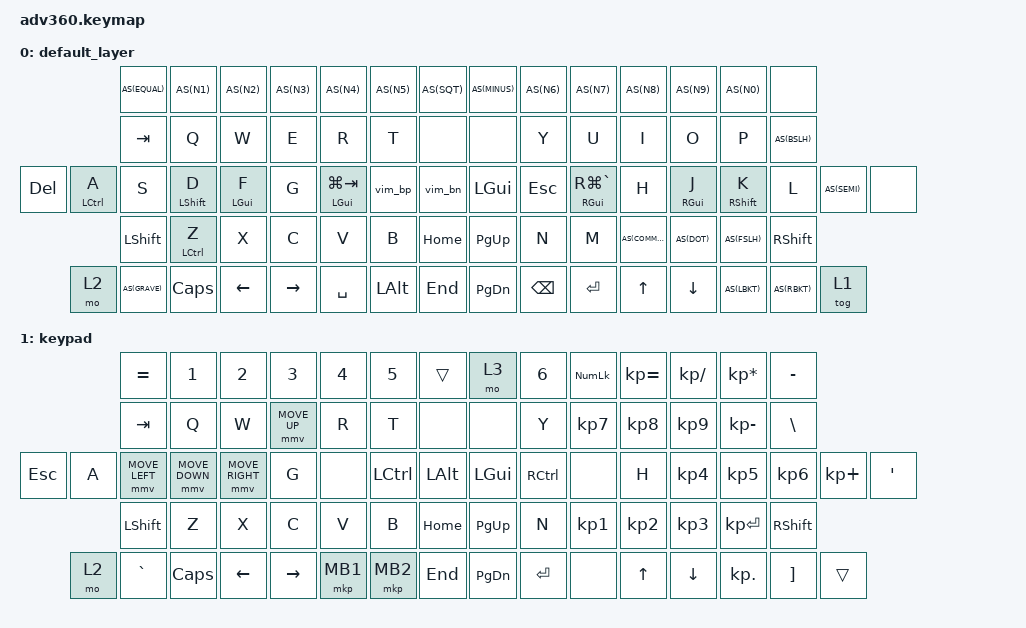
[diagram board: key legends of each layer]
#define ZMK_POINTING_DEFAULT_MOVE_VAL 2000
#include <behaviors.dtsi>
#include <dt-bindings/zmk/keys.h>
#include <dt-bindings/zmk/bt.h>
#include <dt-bindings/zmk/rgb.h>
#include <dt-bindings/zmk/stp.h>
#include <dt-bindings/zmk/backlight.h>
#include <dt-bindings/zmk/pointing.h>

#define AS(keycode) &as LS(keycode) keycode     // Autoshift Macro

#define KEYS_LEFT 0 1 2 3 4 5 6 \
                  14 15 16 17 18 19 20 \
                  28 29 30 31 32 33 34 \
                  46 47 48 49 50 51 \
                  66 67 68 69 70

#define KEYS_RIGHT 7 8 9 10 11 12 13 \
                   21 22 23 24 25 26 27 \
                   39 40 41 42 43 44 45 \
                   60 61 62 63 64 65 \
                   77 78 79 80 81

#define THUMBS_LEFT 35 36 54 71 72 73

#define THUMBS_RIGHT 37 38 57 74 75 76

#define THUMBS THUMBS_LEFT THUMBS_RIGHT

/ {
    macros {
        vim_bp: vim_bp {
                compatible = "zmk,behavior-macro";
                #binding-cells = <0>;
                wait-ms = <40>;
                tap-ms = <40>;
                bindings
                    = <&kp ESC &kp ESC>
                    , <&kp COLON &kp B &kp P>
                    , <&kp ENTER>
                    ;
        };
        vim_bn: vim_bn {
                compatible = "zmk,behavior-macro";
                #binding-cells = <0>;
                wait-ms = <40>;
                tap-ms = <40>;
                bindings
                    = <&kp ESC &kp ESC>
                    , <&kp COLON &kp B &kp N>
                    , <&kp ENTER>
                    ;
        };
    };
    behaviors {
      #include "macros.dtsi"
      #include "version.dtsi"
hml: home_row_mod_left {
            compatible = "zmk,behavior-hold-tap";
            #binding-cells = <2>;
            flavor = "balanced";
            require-prior-idle-ms = <150>;
            tapping-term-ms = <280>;
            quick-tap-ms = <175>;
            bindings = <&kp>, <&kp>;
            hold-trigger-key-positions = <KEYS_RIGHT>; // List of keys on the right side of the keyboard
            hold-trigger-on-release;
        };
        hmr: home_row_mod_right {
            compatible = "zmk,behavior-hold-tap";
            #binding-cells = <2>;
            flavor = "balanced";
            require-prior-idle-ms = <150>;
            tapping-term-ms = <280>;
            quick-tap-ms = <175>;
            bindings = <&kp>, <&kp>;
            hold-trigger-key-positions = <KEYS_LEFT>; // List of keys on the left side of the keyboard
            hold-trigger-on-release;
        };
     as: auto_shift {
            compatible = "zmk,behavior-hold-tap";
            #binding-cells = <2>;
            tapping_term_ms = <135>;
            quick_tap_ms = <0>;
            flavor = "tap-preferred";
            bindings = <&kp>, <&kp>;
        };
    };

  keymap {
    compatible = "zmk,keymap";
      default_layer {
            bindings = <
                AS(EQUAL) AS(N1)    AS(N2)   AS(N3)   AS(N4)     AS(N5) AS(SQT)                                                           AS(MINUS) AS(N6) AS(N7) AS(N8)    AS(N9)   AS(N0)   &none
                &kp TAB   &kp Q     &kp W    &kp E    &kp R      &kp T  &none                                                            &none &kp Y  &kp U  &kp I     &kp O    &kp P    AS(BSLH)
                &kp DEL   &hml LCTRL A     &kp S    &hml LSHIFT D    &hml LGUI F      &kp G  &mt LGUI LG(TAB)        &vim_bp &vim_bn &kp LGUI  &kp ESC           &mt RGUI RG(GRAVE) &kp H  &hmr RGUI J  &hmr RSHIFT K     &kp L    AS(SEMI) &none
                &kp LSHFT &mt LCTRL Z     &kp X    &kp C    &kp V      &kp B                            &kp HOME &kp PG_UP                           &kp N  &kp M  AS(COMMA) AS(DOT)  AS(FSLH) &kp RSHFT
                &mo 2     AS(GRAVE) &kp CAPS &kp LEFT &kp RIGHT                &kp SPACE &kp LALT &kp END  &kp PG_DN &kp BSPC &kp ENTER              &kp UP &kp DOWN  AS(LBKT) AS(RBKT) &tog 1
            >;
        };
        keypad {
            bindings = <
                &kp EQUAL &kp N1    &kp N2   &kp N3   &kp N4     &kp N5 &trans                                                           &mo 3 &kp N6 &kp KP_NUM &kp KP_EQUAL &kp KP_DIVIDE &kp KP_MULTIPLY &kp MINUS
                &kp TAB   &kp Q     &kp W    &mmv MOVE_UP    &kp R      &kp T  &none                                                            &none &kp Y  &kp KP_N7  &kp KP_N8    &kp KP_N9     &kp KP_MINUS    &kp BSLH
                &kp ESC   &kp A  &mmv MOVE_LEFT    &mmv MOVE_DOWN    &mmv MOVE_RIGHT      &kp G  &none           &kp LCTRL &kp LALT &kp LGUI  &kp RCTRL           &none &kp H  &kp KP_N4  &kp KP_N5    &kp KP_N6     &kp KP_PLUS     &kp SQT
                &kp LSHFT &kp Z     &kp X    &kp C    &kp V      &kp B                            &kp HOME &kp PG_UP                           &kp N  &kp KP_N1  &kp KP_N2    &kp KP_N3     &kp KP_ENTER    &kp RSHFT
                &mo 2     &kp GRAVE &kp CAPS &kp LEFT &kp RIGHT                &mkp MB1 &mkp MB2   &kp END  &kp PG_DN &kp ENTER &none              &kp UP     &kp DOWN     &kp KP_DOT    &kp RBKT        &trans
            >;
        };

  };
};
